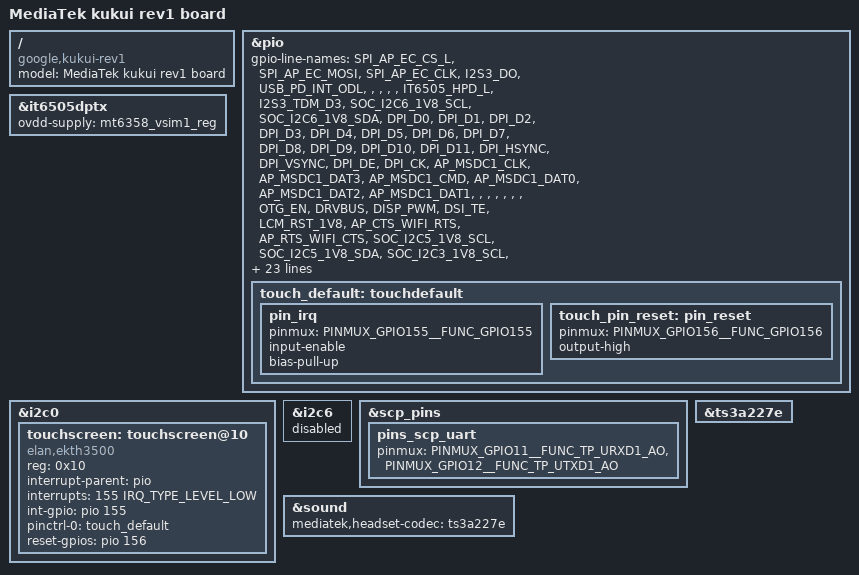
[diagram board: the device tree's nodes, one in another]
// SPDX-License-Identifier: (GPL-2.0 OR MIT)
/*
 * Copyright (c) 2018 Google LLC
 */

/dts-v1/;
#include "mt8183-kukui.dtsi"

/ {
	model = "MediaTek kukui rev1 board";
	compatible = "google,kukui-rev1", "google,kukui", "mediatek,mt8183";
};

&pio {
	/* 192 lines */
	gpio-line-names =
		"SPI_AP_EC_CS_L",
		"SPI_AP_EC_MOSI",
		"SPI_AP_EC_CLK",
		"I2S3_DO",
		"USB_PD_INT_ODL",
		"",
		"",
		"",
		"",
		"IT6505_HPD_L",
		"I2S3_TDM_D3",
		"SOC_I2C6_1V8_SCL",
		"SOC_I2C6_1V8_SDA",
		"DPI_D0",
		"DPI_D1",
		"DPI_D2",
		"DPI_D3",
		"DPI_D4",
		"DPI_D5",
		"DPI_D6",
		"DPI_D7",
		"DPI_D8",
		"DPI_D9",
		"DPI_D10",
		"DPI_D11",
		"DPI_HSYNC",
		"DPI_VSYNC",
		"DPI_DE",
		"DPI_CK",
		"AP_MSDC1_CLK",
		"AP_MSDC1_DAT3",
		"AP_MSDC1_CMD",
		"AP_MSDC1_DAT0",
		"AP_MSDC1_DAT2",
		"AP_MSDC1_DAT1",
		"",
		"",
		"",
		"",
		"",
		"",
		"OTG_EN",
		"DRVBUS",
		"DISP_PWM",
		"DSI_TE",
		"LCM_RST_1V8",
		"AP_CTS_WIFI_RTS",
		"AP_RTS_WIFI_CTS",
		"SOC_I2C5_1V8_SCL",
		"SOC_I2C5_1V8_SDA",
		"SOC_I2C3_1V8_SCL",
		"SOC_I2C3_1V8_SDA",
		"",
		"",
		"",
		"",
		"",
		"",
		"",
		"",
		"",
		"",
		"",
		"",
		"",
		"",
		"",
		"",
		"",
		"",
		"",
		"",
		"",
		"",
		"",
		"",
		"",
		"",
		"",
		"",
		"",
		"SOC_I2C1_1V8_SDA",
		"SOC_I2C0_1V8_SDA",
		"SOC_I2C0_1V8_SCL",
		"SOC_I2C1_1V8_SCL",
		"AP_SPI_H1_MISO",
		"AP_SPI_H1_CS_L",
		"AP_SPI_H1_MOSI",
		"AP_SPI_H1_CLK",
		"I2S5_BCK",
		"I2S5_LRCK",
		"I2S5_DO",
		"BOOTBLOCK_EN_L",
		"MT8183_KPCOL0",
		"SPI_AP_EC_MISO",
		"UART_DBG_TX_AP_RX",
		"UART_AP_TX_DBG_RX",
		"I2S2_MCK",
		"I2S2_BCK",
		"CLK_5M_WCAM",
		"CLK_2M_UCAM",
		"I2S2_LRCK",
		"I2S2_DI",
		"SOC_I2C2_1V8_SCL",
		"SOC_I2C2_1V8_SDA",
		"SOC_I2C4_1V8_SCL",
		"SOC_I2C4_1V8_SDA",
		"",
		"SCL8",
		"SDA8",
		"FCAM_PWDN_L",
		"",
		"",
		"",
		"",
		"",
		"",
		"",
		"",
		"",
		"",
		"",
		"",
		"",
		"",
		"",
		"",
		"",
		"",
		"",
		"",
		"",
		"",
		"",
		"",
		"",
		"I2S_PMIC",
		"I2S_PMIC",
		"I2S_PMIC",
		"I2S_PMIC",
		"I2S_PMIC",
		"I2S_PMIC",
		"I2S_PMIC",
		"I2S_PMIC",
		"",
		"",
		"",
		"",
		"",
		"",
		/*
		 * AP_FLASH_WP_L is crossystem ABI. Rev1 schematics
		 * call it BIOS_FLASH_WP_R_L.
		 */
		"AP_FLASH_WP_L",
		"EC_AP_INT_ODL",
		"IT6505_INT_ODL",
		"H1_INT_OD_L",
		"",
		"",
		"",
		"",
		"",
		"",
		"",
		"AP_SPI_FLASH_MISO",
		"AP_SPI_FLASH_CS_L",
		"AP_SPI_FLASH_MOSI",
		"AP_SPI_FLASH_CLK",
		"DA7219_IRQ",
		"",
		"",
		"",
		"",
		"",
		"",
		"",
		"",
		"",
		"",
		"",
		"",
		"",
		"",
		"",
		"",
		"",
		"",
		"",
		"",
		"",
		"",
		"",
		"",
		"",
		"";

	touch_default: touchdefault {
		pin_irq {
			pinmux = <PINMUX_GPIO155__FUNC_GPIO155>;
			input-enable;
			bias-pull-up;
		};

		touch_pin_reset: pin_reset {
			pinmux = <PINMUX_GPIO156__FUNC_GPIO156>;
			output-high;
		};
	};
};

&it6505dptx {
	ovdd-supply = <&mt6358_vsim1_reg>;
	/delete-property/ no-laneswap;
};

&i2c0 {
	status = "okay";

	touchscreen: touchscreen@10 {
		compatible = "elan,ekth3500";
		reg = <0x10>;
		interrupt-parent = <&pio>;
		interrupts = <155 IRQ_TYPE_LEVEL_LOW>;
		int-gpio = <&pio 155 0>;
		pinctrl-names = "default";
		pinctrl-0 = <&touch_default>;

		reset-gpios = <&pio 156 0>;
	};
};

&i2c6 {
	status = "disabled";
};

&scp_pins {
	pins_scp_uart {
		pinmux = <PINMUX_GPIO11__FUNC_TP_URXD1_AO>,
			 <PINMUX_GPIO12__FUNC_TP_UTXD1_AO>;
	};
};

&sound {
	mediatek,headset-codec = <&ts3a227e>;
};

&ts3a227e {
	status = "okay";
};
